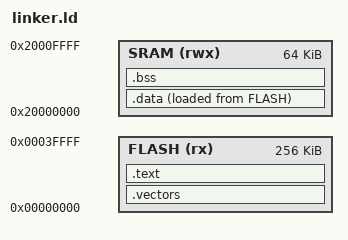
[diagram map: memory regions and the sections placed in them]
ENTRY(Reset_Handler)

MEMORY
{
  FLASH (rx) : ORIGIN = 0x00000000, LENGTH = 256K
  SRAM (rwx) : ORIGIN = 0x20000000, LENGTH = 64K
}

_stack_top = ORIGIN(SRAM) + LENGTH(SRAM);

SECTIONS
{
  .vectors : ALIGN(4)
  {
    KEEP(*(.vectors))
  } > FLASH

  .text : ALIGN(4)
  {
    *(.text*)
    *(.rodata*)
  } > FLASH

  .data : ALIGN(4)
  {
    _sdata = .;
    KEEP(*(.data*))
    _edata = .;
  } > SRAM AT > FLASH

  _sidata = LOADADDR(.data);

  .bss (NOLOAD) : ALIGN(4)
  {
    _sbss = .;
    *(.bss*)
    *(COMMON)
    _ebss = .;
  } > SRAM
}
